# PIC32MX470F512H register map
Registers are 32-bit, access not given, reset 0x0 unless marked. A register's access mark holds for its fields unless they carry their own. Offsets are from the block's base; lines under a group give offsets from that group; [hi:lo] are bit positions; {n}, {i} and the like mark numbered series; 'fields as' and 'values as' point back to an identical list; <NAME> marks a mode.

## Memory map
0xBF800000 WDT size 0x10 — WDT peripheral
0xBF800200 RTCC size 0x60 — RTCC peripheral
0xBF800600 TMR1 size 0x30 — TMR1 peripheral
0xBF800800 TMR2 size 0x30 — TMR2 peripheral
0xBF800A00 TMR3 size 0x30 — TMR3 peripheral
0xBF800C00 TMR4 size 0x30 — TMR4 peripheral
0xBF800E00 TMR5 size 0x30 — TMR5 peripheral
0xBF802000 ICAP1 size 0x20 — ICAP1 peripheral
0xBF802200 ICAP2 size 0x20 — ICAP2 peripheral
0xBF802400 ICAP3 size 0x20 — ICAP3 peripheral
0xBF802600 ICAP4 size 0x20 — ICAP4 peripheral
0xBF802800 ICAP5 size 0x20 — ICAP5 peripheral
0xBF803000 OCMP1 size 0x30 — OCMP1 peripheral
0xBF803200 OCMP2 size 0x30 — OCMP2 peripheral
0xBF803400 OCMP3 size 0x30 — OCMP3 peripheral
0xBF803600 OCMP4 size 0x30 — OCMP4 peripheral
0xBF803800 OCMP5 size 0x30 — OCMP5 peripheral
0xBF805000 I2C1 size 0x70 — I2C1 peripheral
0xBF805100 I2C2 size 0x70 — I2C2 peripheral
0xBF805800 SPI1 size 0x50 — SPI1 peripheral
0xBF805A00 SPI2 size 0x50 — SPI2 peripheral
0xBF806000 UART1 size 0x50 — UART1 peripheral
0xBF806200 UART2 size 0x50 — UART2 peripheral
0xBF806400 UART3 size 0x50 — UART3 peripheral
0xBF806600 UART4 size 0x50 — UART4 peripheral
0xBF807000 PMP size 0x70 — PMP peripheral
0xBF809000 ADC10 size 0x170 — ADC10 peripheral
0xBF809800 CVR size 0x10 — CVR peripheral
0xBF80A000 CMP1 size 0x10 — CMP1 peripheral
0xBF80A010 CMP2 size 0x10 — CMP2 peripheral
0xBF80A060 CMP size 0x10 — CMP peripheral
0xBF80A200 CTMU size 0x10 — CTMU peripheral
0xBF80F000 OSC size 0x40 — OSC peripheral
0xBF80F200 CFG size 0xA0 — CFG peripheral
0xBF80F400 NVM size 0x50 — NVM peripheral
0xBF80F600 RCON size 0x20 — RCON peripheral
0xBF80FA04 PPS size 0x2B0 — PPS peripheral
0xBF881000 INT size 0x150 — INT peripheral
0xBF882000 BMX size 0x80 — BMX peripheral
0xBF883000 DMAC size 0x60 — DMAC peripheral
0xBF883060 DMAC0 size 0xC0 — DMAC0 peripheral
0xBF883120 DMAC1 size 0xC0 — DMAC1 peripheral
0xBF8831E0 DMAC2 size 0xC0 — DMAC2 peripheral
0xBF8832A0 DMAC3 size 0xC0 — DMAC3 peripheral
0xBF884000 PCACHE size 0xD0 — PCACHE peripheral
0xBF885040 USB size 0x3C0 — USB peripheral
0xBF886100 PORTB size 0xA0 — PORTB peripheral
0xBF886200 PORTC size 0xA0 — PORTC peripheral
0xBF886300 PORTD size 0xA0 — PORTD peripheral
0xBF886400 PORTE size 0xA0 — PORTE peripheral
0xBF886500 PORTF size 0xA0 — PORTF peripheral
0xBF886600 PORTG size 0xA0 — PORTG peripheral

## Interrupts
0 CORE_TIMER (INT)
1 CORE_SOFTWARE_0 (INT)
2 CORE_SOFTWARE_1 (INT)
3 EXTERNAL_0 (INT)
4 TIMER_1 (INT)
5 INPUT_CAPTURE_1 (INT)
6 OUTPUT_COMPARE_1 (INT)
7 EXTERNAL_1 (INT)
8 TIMER_2 (INT)
9 INPUT_CAPTURE_2 (INT)
10 OUTPUT_COMPARE_2 (INT)
11 EXTERNAL_2 (INT)
12 TIMER_3 (INT)
13 INPUT_CAPTURE_3 (INT)
14 OUTPUT_COMPARE_3 (INT)
15 EXTERNAL_3 (INT)
16 TIMER_4 (INT)
17 INPUT_CAPTURE_4 (INT)
18 OUTPUT_COMPARE_4 (INT)
19 EXTERNAL_4 (INT)
20 TIMER_5 (INT)
21 INPUT_CAPTURE_5 (INT)
22 OUTPUT_COMPARE_5 (INT)
23 ADC (INT)
24 FAIL_SAFE_MONITOR (INT)
25 RTCC (INT)
26 FCE (INT)
27 COMPARATOR_1 (INT)
28 COMPARATOR_2 (INT)
29 USB_1 (INT)
30 SPI_1 (INT)
31 UART_1 (INT)
32 I2C_1 (INT)
33 CHANGE_NOTICE (INT)
34 PMP (INT)
35 SPI_2 (INT)
36 UART_2 (INT)
37 I2C_2 (INT)
38 UART_3 (INT)
39 UART_4 (INT)
41 CTMU (INT)
42 DMA_0 (INT)
43 DMA_1 (INT)
44 DMA_2 (INT)
45 DMA_3 (INT)

## BMX — BMX peripheral
Base 0xBF882000
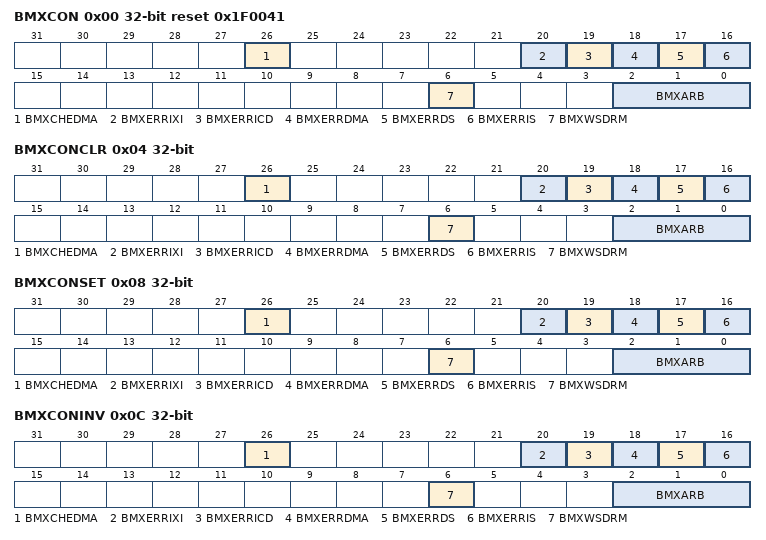
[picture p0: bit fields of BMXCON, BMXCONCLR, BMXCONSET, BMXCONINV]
0x00 BMXCON reset 0x1F0041
  [26] BMXCHEDMA, [20] BMXERRIXI, [19] BMXERRICD, [18] BMXERRDMA, [17] BMXERRDS, [16] BMXERRIS, [6] BMXWSDRM, [2:0] BMXARB
0x04 BMXCONCLR
  fields as BMXCON
0x08 BMXCONSET
  fields as BMXCON
0x0C BMXCONINV
  fields as BMXCON
0x10 BMXDKPBA
0x14 BMXDKPBACLR
  [31:0] BMXDKPBA
0x18 BMXDKPBASET
  [31:0] BMXDKPBA
0x1C BMXDKPBAINV
  [31:0] BMXDKPBA
0x20 BMXDUDBA
0x24 BMXDUDBACLR
  [31:0] BMXDUDBA
0x28 BMXDUDBASET
  [31:0] BMXDUDBA
0x2C BMXDUDBAINV
  [31:0] BMXDUDBA
0x30 BMXDUPBA
0x34 BMXDUPBACLR
  [31:0] BMXDUPBA
0x38 BMXDUPBASET
  [31:0] BMXDUPBA
0x3C BMXDUPBAINV
  [31:0] BMXDUPBA
0x40 BMXDRMSZ reset 0x20000
0x50 BMXPUPBA
0x54 BMXPUPBACLR
  [31:0] BMXPUPBA
0x58 BMXPUPBASET
  [31:0] BMXPUPBA
0x5C BMXPUPBAINV
  [31:0] BMXPUPBA
0x60 BMXPFMSZ reset 0x80000
0x70 BMXBOOTSZ reset 0x3000
